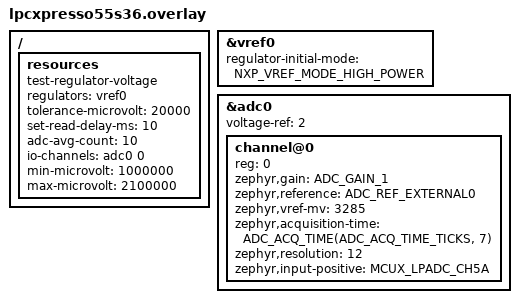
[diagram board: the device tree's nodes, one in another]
/*
 * Copyright 2023, 2025 NXP
 * SPDX-License-Identifier: Apache-2.0
 */

#include <zephyr/dt-bindings/adc/mcux-lpadc.h>
#include <zephyr/dt-bindings/regulator/nxp_vref.h>

/ {
	resources: resources {
		compatible = "test-regulator-voltage";
		regulators = <&vref0>;
		tolerance-microvolt = <20000>;
		set-read-delay-ms = <10>;
		adc-avg-count = <10>;
		io-channels = <&adc0 0>;
		min-microvolt = <1000000>;
		max-microvolt = <2100000>;
	};
};

&vref0 {
	regulator-initial-mode = <NXP_VREF_MODE_HIGH_POWER>;
};

&adc0 {
	#address-cells = <1>;
	#size-cells = <0>;

	/* In this case, the LPADC reference source cannot be set to VREFO,
	 * switch the reference source to VDDA. The user needs to measure the
	 * voltage of VDDA pin to set the value of 'zephyr,vref-mv'.
	 */
	voltage-ref = <2>;

	channel@0 {
		reg = <0>;
		zephyr,gain = "ADC_GAIN_1";
		zephyr,reference = "ADC_REF_EXTERNAL0";
		/* VDDA is not accurate to 3300mV, after measurement,
		 * the actual voltage is 3285mV.
		 */
		zephyr,vref-mv = <3285>;
		zephyr,acquisition-time = <ADC_ACQ_TIME(ADC_ACQ_TIME_TICKS, 7)>;
		zephyr,resolution = <12>;
		/* ADC0 channel 5 A-side is internally connected to VREFO. */
		zephyr,input-positive = <MCUX_LPADC_CH5A>;
	};
};
